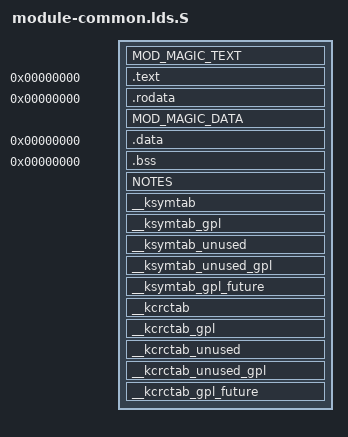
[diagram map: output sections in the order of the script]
/*
 * Common module linker script, always used when linking a module.
 * Archs are free to supply their own linker scripts.  ld will
 * combine them automatically.
 */

/* .data.foo are generated by gcc itself with -fdata-sections,
 * whereas double-dot sections (like .data..percpu) are generated
 * by kernel's magic macros.
 *
 * Since this script does not specify what to do with double-dot sections,
 * ld -r will coalesce all .data..foo input sections into one .data..foo
 * output section, all .data..bar input sections into one .data..bar
 * output section and so on. This is exactly what we want.
 *
 * Same goes for .text, .bss and .rodata. In case of .rodata, various
 * .rodata.foo sections are generated by gcc even without -fdata-sections
 */

#include <asm/page.h>
#include <asm-generic/vmlinux.lds.h>
#include <asm/cache.h>

SECTIONS {
	/* Put magic .text..foo sections */
	MOD_MAGIC_TEXT

	/* Coalesce sections produced by gcc -ffunction-sections */
	.text 0 : AT(0) {
		ALL(.init.text)
		ALL(.text)
		ALL(.exit.text)
	}

	/* Coalesce sections produced by gcc -fdata-sections */
	.rodata 0 : AT(0) {
		ALL(.rodata)
	}

	/* Put magic .data..foo sections */
	MOD_MAGIC_DATA

	.data 0 : AT(0) {
		ALL(.data)
	}
	.bss 0 : AT(0) {
		ALL(.sbss)
		ALL(.bss..page_aligned)
		ALL(.bss)
	}

	NOTES

	/DISCARD/ : { ALL(.discard) }

	__ksymtab		: { *(SORT(___ksymtab+*)) }
	__ksymtab_gpl		: { *(SORT(___ksymtab_gpl+*)) }
	__ksymtab_unused	: { *(SORT(___ksymtab_unused+*)) }
	__ksymtab_unused_gpl	: { *(SORT(___ksymtab_unused_gpl+*)) }
	__ksymtab_gpl_future	: { *(SORT(___ksymtab_gpl_future+*)) }
	__kcrctab		: { *(SORT(___kcrctab+*)) }
	__kcrctab_gpl		: { *(SORT(___kcrctab_gpl+*)) }
	__kcrctab_unused	: { *(SORT(___kcrctab_unused+*)) }
	__kcrctab_unused_gpl	: { *(SORT(___kcrctab_unused_gpl+*)) }
	__kcrctab_gpl_future	: { *(SORT(___kcrctab_gpl_future+*)) }
}
